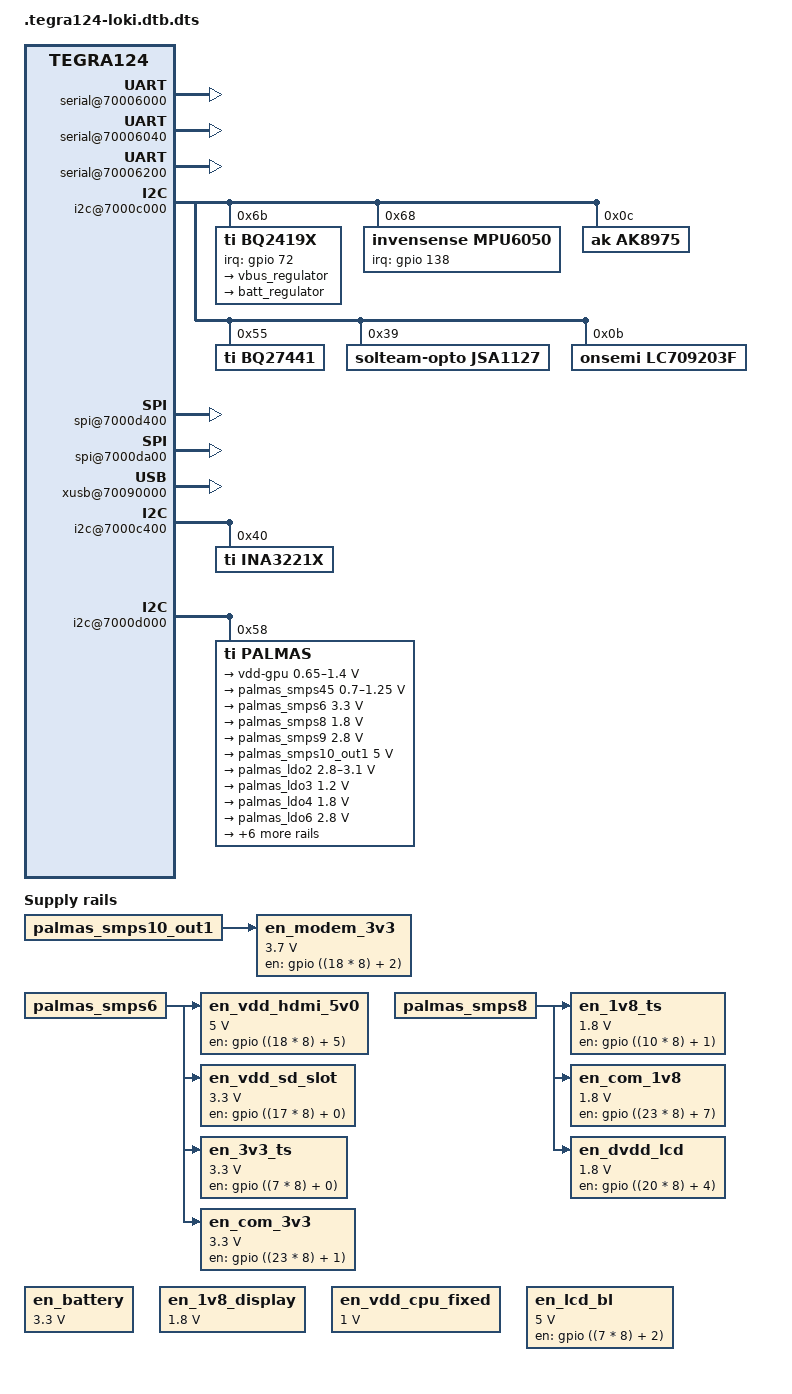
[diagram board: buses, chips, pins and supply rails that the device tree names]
# 1 "arch/arm/boot/dts/tegra124-loki.dts"
# 1 "<built-in>"
# 1 "<command-line>"
# 1 "arch/arm/boot/dts/tegra124-loki.dts"
# 1 "arch/arm/boot/dts/tegra124-loki-e2530-a01.dts" 1
# 1 "arch/arm/boot/dts/tegra124-loki-common.dtsi" 1
/dts-v1/;

# 1 "arch/arm/boot/dts/tegra124.dtsi" 1
# 1 "/media/madman/Extended_Linux/21.8_l4t_build/kernel/arch/arm/boot/dts/include/dt-bindings/gpio/tegra-gpio.h" 1
# 13 "/media/madman/Extended_Linux/21.8_l4t_build/kernel/arch/arm/boot/dts/include/dt-bindings/gpio/tegra-gpio.h"
# 1 "/media/madman/Extended_Linux/21.8_l4t_build/kernel/arch/arm/boot/dts/include/dt-bindings/gpio/gpio.h" 1
# 14 "/media/madman/Extended_Linux/21.8_l4t_build/kernel/arch/arm/boot/dts/include/dt-bindings/gpio/tegra-gpio.h" 2
# 2 "arch/arm/boot/dts/tegra124.dtsi" 2
# 1 "/media/madman/Extended_Linux/21.8_l4t_build/kernel/arch/arm/boot/dts/include/dt-bindings/input/input.h" 1
# 3 "arch/arm/boot/dts/tegra124.dtsi" 2
# 1 "/media/madman/Extended_Linux/21.8_l4t_build/kernel/arch/arm/boot/dts/include/dt-bindings/interrupt-controller/arm-gic.h" 1







# 1 "/media/madman/Extended_Linux/21.8_l4t_build/kernel/arch/arm/boot/dts/include/dt-bindings/interrupt-controller/irq.h" 1
# 9 "/media/madman/Extended_Linux/21.8_l4t_build/kernel/arch/arm/boot/dts/include/dt-bindings/interrupt-controller/arm-gic.h" 2
# 4 "arch/arm/boot/dts/tegra124.dtsi" 2
# 1 "/media/madman/Extended_Linux/21.8_l4t_build/kernel/arch/arm/boot/dts/include/dt-bindings/ata/ahci-tegra.h" 1
# 5 "arch/arm/boot/dts/tegra124.dtsi" 2

/include/ "tegra124-soc.dtsi"

/ {
 compatible = "nvidia,tegra124";
 interrupt-parent = <&intc>;
 #address-cells = <2>;
 #size-cells = <2>;

 mc {
  compatible = "nvidia,tegra-mc";

  reg-ranges = <9>;
  reg = <0x0 0x70019000 0x0 0x00c>,
        <0x0 0x70019050 0x0 0x19c>,
        <0x0 0x70019200 0x0 0x024>,
        <0x0 0x7001929c 0x0 0x1b8>,
        <0x0 0x70019464 0x0 0x198>,
        <0x0 0x70019604 0x0 0x3b0>,
        <0x0 0x700199bc 0x0 0x020>,
        <0x0 0x700199f8 0x0 0x08c>,
        <0x0 0x70019ab4 0x0 0x54c>;

  interrupts = <0 77 0x4>;
  int_count = <8>;
  int_mask = <0x13D40>;

  channels = <1>;
 };

 intc: interrupt-controller@50041000 {
  compatible = "arm,cortex-a15-gic";
  interrupt-controller;
  #interrupt-cells = <3>;
  reg = <0x0 0x50041000 0x0 0x1000>,
        <0x0 0x50042000 0x0 0x0100>;
 };

 lic: interrupt-controller@60004000 {
  compatible = "nvidia,tegra-gic";
  interrupt-controller;
  reg = <0x0 0x60004000 0x0 0x40>,
        <0x0 0x60004100 0x0 0x40>,
        <0x0 0x60004200 0x0 0x40>,
        <0x0 0x60004300 0x0 0x40>,
        <0x0 0x60004400 0x0 0x40>;
        };

 cpus {
  #address-cells = <1>;
  #size-cells = <0>;

  cpu@0 {
   device_type = "cpu";
   compatible = "arm,cortex-a15";
   reg = <0>;
  };

  cpu@1 {
   device_type = "cpu";
   compatible = "arm,cortex-a15";
   reg = <1>;
  };

  cpu@2 {
   device_type = "cpu";
   compatible = "arm,cortex-a15";
   reg = <2>;
  };

  cpu@3 {
   device_type = "cpu";
   compatible = "arm,cortex-a15";
   reg = <3>;
  };
 };

 timer {
  compatible = "arm,armv7-timer";
  interrupts = <1 13 0xf04
         1 14 0xf04>;
 };

 dfll@70110000 {
   compatible = "nvidia,tegra124-dfll";
   reg = <0x0 0x70110000 0x0 0x400>;
   out-clock-name="dfll_cpu";
   status = "disabled";
 };
};
# 4 "arch/arm/boot/dts/tegra124-loki-common.dtsi" 2

# 1 "/media/madman/Extended_Linux/21.8_l4t_build/kernel/arch/arm/boot/dts/tegra124-platforms/tegra124-loki-gpio-default.dtsi" 1


/ {
 gpio: gpio@6000d000 {
  gpio-init-names = "default";
  gpio-init-0 = <&gpio_default>;

  gpio_default: default {
   gpio-input = < ((23 * 8) + 3)
     ((22 * 8) + 3)
     ((6 * 8) + 0)
     ((6 * 8) + 1)
     ((7 * 8) + 4)
     ((6 * 8) + 2)
     ((6 * 8) + 3)
     ((9 * 8) + 0)
     ((9 * 8) + 2)
     ((10 * 8) + 3)
     ((10 * 8) + 2)
     ((8 * 8) + 6)
     ((8 * 8) + 5)
     ((8 * 8) + 1)
     ((2 * 8) + 7)
     ((8 * 8) + 0)
     ((16 * 8) + 0)
     ((16 * 8) + 5)
     ((18 * 8) + 4)
     ((18 * 8) + 6)
     ((18 * 8) + 7)
     ((17 * 8) + 2)
     ((17 * 8) + 4)
     ((17 * 8) + 6)
     ((17 * 8) + 7)
     ((20 * 8) + 0)
     ((20 * 8) + 2)
     ((20 * 8) + 5)
     ((13 * 8) + 7)
     ((10 * 8) + 6)>;
   gpio-output-low = <((23 * 8) + 7)
     ((23 * 8) + 1)
     ((27 * 8) + 3)
     ((27 * 8) + 6)
     ((7 * 8) + 2)
     ((7 * 8) + 3)
     ((7 * 8) + 5)
     ((7 * 8) + 6)
     ((7 * 8) + 7)
     ((7 * 8) + 0)
     ((10 * 8) + 1)
     ((10 * 8) + 4)
     ((8 * 8) + 3)
     ((8 * 8) + 4)
     ((8 * 8) + 7)
     ((28 * 8) + 5)
     ((16 * 8) + 6)
     ((17 * 8) + 0)
     ((17 * 8) + 1)
     ((18 * 8) + 5)
     ((17 * 8) + 3)
     ((30 * 8) + 1)
     ((20 * 8) + 1)
     ((20 * 8) + 4)
     ((10 * 8) + 5)>;
   gpio-output-high = <((10 * 8) + 0)
     ((16 * 8) + 7)
     ((21 * 8) + 3)
     ((17 * 8) + 5)
     ((20 * 8) + 6)>;
  };
 };
};
# 6 "arch/arm/boot/dts/tegra124-loki-common.dtsi" 2
# 1 "/media/madman/Extended_Linux/21.8_l4t_build/kernel/arch/arm/boot/dts/tegra124-platforms/tegra124-loki-pinmux.dtsi" 1
# 1 "/media/madman/Extended_Linux/21.8_l4t_build/kernel/arch/arm/boot/dts/include/dt-bindings/pinctrl/pinctrl-tegra.h" 1
# 2 "/media/madman/Extended_Linux/21.8_l4t_build/kernel/arch/arm/boot/dts/tegra124-platforms/tegra124-loki-pinmux.dtsi" 2

/ {
 pinmux: pinmux {
  pinctrl-names = "default", "drive", "unused";
  pinctrl-0 = <&pinmux_default>;
  pinctrl-1 = <&drive_default>;
  pinctrl-2 = <&pinmux_unused_lowpower>;

  pinmux_default: common {
   dap_mclk1_pw4 {
    nvidia,pins = "dap_mclk1_pw4";
    nvidia,function = "extperiph1";
    nvidia,enable-input = <0>;
    nvidia,pull = <0>;
    nvidia,tristate = <0>;
   };

   dap2_din_pa4 {
    nvidia,pins = "dap2_din_pa4";
    nvidia,function = "i2s1";
    nvidia,enable-input = <1>;
    nvidia,pull = <0>;
    nvidia,tristate = <1>;
   };

   dap2_dout_pa5 {
    nvidia,pins = "dap2_dout_pa5";
    nvidia,function = "i2s1";
    nvidia,enable-input = <1>;
    nvidia,pull = <0>;
    nvidia,tristate = <0>;
   };

   dap2_fs_pa2 {
    nvidia,pins = "dap2_fs_pa2";
    nvidia,function = "i2s1";
    nvidia,enable-input = <1>;
    nvidia,pull = <0>;
    nvidia,tristate = <0>;
   };

   dap2_sclk_pa3 {
    nvidia,pins = "dap2_sclk_pa3";
    nvidia,function = "i2s1";
    nvidia,enable-input = <1>;
    nvidia,pull = <0>;
    nvidia,tristate = <0>;
   };

   dvfs_pwm_px0 {
    nvidia,pins = "dvfs_pwm_px0";
    nvidia,function = "cldvfs";
    nvidia,enable-input = <0>;
    nvidia,pull = <0>;
    nvidia,tristate = <0>;
   };

   dvfs_clk_px2 {
    nvidia,pins = "dvfs_clk_px2";
    nvidia,function = "cldvfs";
    nvidia,enable-input = <0>;
    nvidia,pull = <0>;
    nvidia,tristate = <0>;
   };

   ulpi_clk_py0 {
    nvidia,pins = "ulpi_clk_py0";
    nvidia,function = "spi1";
    nvidia,enable-input = <0>;
    nvidia,pull = <0>;
    nvidia,tristate = <0>;
   };

   ulpi_dir_py1 {
    nvidia,pins = "ulpi_dir_py1";
    nvidia,function = "spi1";
    nvidia,enable-input = <1>;
    nvidia,pull = <0>;
    nvidia,tristate = <0>;
   };

   ulpi_nxt_py2 {
    nvidia,pins = "ulpi_nxt_py2";
    nvidia,function = "spi1";
    nvidia,enable-input = <0>;
    nvidia,pull = <0>;
    nvidia,tristate = <0>;
   };

   ulpi_stp_py3 {
    nvidia,pins = "ulpi_stp_py3";
    nvidia,function = "spi1";
    nvidia,enable-input = <0>;
    nvidia,pull = <0>;
    nvidia,tristate = <0>;
   };

   gen2_i2c_scl_pt5 {
    nvidia,pins = "gen2_i2c_scl_pt5";
    nvidia,function = "i2c2";
    nvidia,enable-input = <1>;
    nvidia,pull = <0>;
    nvidia,tristate = <0>;
    nvidia,lock = <0>;
    nvidia,open-drain = <1>;
   };

   gen2_i2c_sda_pt6 {
    nvidia,pins = "gen2_i2c_sda_pt6";
    nvidia,function = "i2c2";
    nvidia,enable-input = <1>;
    nvidia,pull = <0>;
    nvidia,tristate = <0>;
    nvidia,lock = <0>;
    nvidia,open-drain = <1>;
   };

   cam_i2c_scl_pbb1 {
    nvidia,pins = "cam_i2c_scl_pbb1";
    nvidia,function = "i2c3";
    nvidia,enable-input = <1>;
    nvidia,pull = <0>;
    nvidia,tristate = <0>;
    nvidia,lock = <0>;
    nvidia,open-drain = <1>;
   };

   cam_i2c_sda_pbb2 {
    nvidia,pins = "cam_i2c_sda_pbb2";
    nvidia,function = "i2c3";
    nvidia,enable-input = <1>;
    nvidia,pull = <0>;
    nvidia,tristate = <0>;
    nvidia,lock = <0>;
    nvidia,open-drain = <1>;
   };

   pj7 {
    nvidia,pins = "pj7";
    nvidia,function = "uartd";
    nvidia,enable-input = <0>;
    nvidia,pull = <0>;
    nvidia,tristate = <0>;
   };

   pb0 {
    nvidia,pins = "pb0";
    nvidia,function = "uartd";
    nvidia,enable-input = <1>;
    nvidia,pull = <0>;
    nvidia,tristate = <0>;
   };

   pb1 {
    nvidia,pins = "pb1";
    nvidia,function = "uartd";
    nvidia,enable-input = <1>;
    nvidia,pull = <0>;
    nvidia,tristate = <0>;
   };

   pk7 {
    nvidia,pins = "pk7";
    nvidia,function = "uartd";
    nvidia,enable-input = <0>;
    nvidia,pull = <0>;
    nvidia,tristate = <0>;
   };

   pg4 {
    nvidia,pins = "pg4";
    nvidia,function = "spi4";
    nvidia,enable-input = <0>;
    nvidia,pull = <0>;
    nvidia,tristate = <0>;
   };

   pg5 {
    nvidia,pins = "pg5";
    nvidia,function = "spi4";
    nvidia,enable-input = <0>;
    nvidia,pull = <0>;
    nvidia,tristate = <0>;
   };

   pg6 {
    nvidia,pins = "pg6";
    nvidia,function = "spi4";
    nvidia,enable-input = <0>;
    nvidia,pull = <0>;
    nvidia,tristate = <0>;
   };

   pg7 {
    nvidia,pins = "pg7";
    nvidia,function = "spi4";
    nvidia,enable-input = <1>;
    nvidia,pull = <0>;
    nvidia,tristate = <0>;
   };

   ph1 {
    nvidia,pins = "ph1";
    nvidia,function = "pwm1";
    nvidia,enable-input = <0>;
    nvidia,pull = <0>;
    nvidia,tristate = <0>;
   };

   clk2_out_pw5 {
    nvidia,pins = "clk2_out_pw5";
    nvidia,function = "extperiph2";
    nvidia,enable-input = <0>;
    nvidia,pull = <0>;
    nvidia,tristate = <0>;
   };

   sdmmc1_clk_pz0 {
    nvidia,pins = "sdmmc1_clk_pz0";
    nvidia,function = "sdmmc1";
    nvidia,enable-input = <1>;
    nvidia,pull = <0>;
    nvidia,tristate = <0>;
   };

   sdmmc1_cmd_pz1 {
    nvidia,pins = "sdmmc1_cmd_pz1";
    nvidia,function = "sdmmc1";
    nvidia,enable-input = <1>;
    nvidia,pull = <2>;
    nvidia,tristate = <0>;
   };

   sdmmc1_dat0_py7 {
    nvidia,pins = "sdmmc1_dat0_py7";
    nvidia,function = "sdmmc1";
    nvidia,enable-input = <1>;
    nvidia,pull = <2>;
    nvidia,tristate = <0>;
   };

   sdmmc1_dat1_py6 {
    nvidia,pins = "sdmmc1_dat1_py6";
    nvidia,function = "sdmmc1";
    nvidia,enable-input = <1>;
    nvidia,pull = <2>;
    nvidia,tristate = <0>;
   };

   sdmmc1_dat2_py5 {
    nvidia,pins = "sdmmc1_dat2_py5";
    nvidia,function = "sdmmc1";
    nvidia,enable-input = <1>;
    nvidia,pull = <2>;
    nvidia,tristate = <0>;
   };

   sdmmc1_dat3_py4 {
    nvidia,pins = "sdmmc1_dat3_py4";
    nvidia,function = "sdmmc1";
    nvidia,enable-input = <1>;
    nvidia,pull = <2>;
    nvidia,tristate = <0>;
   };

   sdmmc3_clk_pa6 {
    nvidia,pins = "sdmmc3_clk_pa6";
    nvidia,function = "sdmmc3";
    nvidia,enable-input = <0>;
    nvidia,pull = <0>;
    nvidia,tristate = <0>;
   };

   sdmmc3_cmd_pa7 {
    nvidia,pins = "sdmmc3_cmd_pa7";
    nvidia,function = "sdmmc3";
    nvidia,enable-input = <1>;
    nvidia,pull = <2>;
    nvidia,tristate = <0>;
   };

   sdmmc3_dat0_pb7 {
    nvidia,pins = "sdmmc3_dat0_pb7";
    nvidia,function = "sdmmc3";
    nvidia,enable-input = <1>;
    nvidia,pull = <2>;
    nvidia,tristate = <0>;
   };

   sdmmc3_dat1_pb6 {
    nvidia,pins = "sdmmc3_dat1_pb6";
    nvidia,function = "sdmmc3";
    nvidia,enable-input = <1>;
    nvidia,pull = <2>;
    nvidia,tristate = <0>;
   };

   sdmmc3_dat2_pb5 {
    nvidia,pins = "sdmmc3_dat2_pb5";
    nvidia,function = "sdmmc3";
    nvidia,enable-input = <1>;
    nvidia,pull = <2>;
    nvidia,tristate = <0>;
   };

   sdmmc3_dat3_pb4 {
    nvidia,pins = "sdmmc3_dat3_pb4";
    nvidia,function = "sdmmc3";
    nvidia,enable-input = <1>;
    nvidia,pull = <2>;
    nvidia,tristate = <0>;
   };

   sdmmc3_clk_lb_out_pee4 {
    nvidia,pins = "sdmmc3_clk_lb_out_pee4";
    nvidia,function = "sdmmc3";
    nvidia,enable-input = <1>;
    nvidia,pull = <2>;
    nvidia,tristate = <0>;
   };

   sdmmc3_clk_lb_in_pee5 {
    nvidia,pins = "sdmmc3_clk_lb_in_pee5";
    nvidia,function = "sdmmc3";
    nvidia,enable-input = <1>;
    nvidia,pull = <2>;
    nvidia,tristate = <0>;
   };

   sdmmc3_cd_n_pv2 {
    nvidia,pins = "sdmmc3_cd_n_pv2";
    nvidia,function = "sdmmc3";
    nvidia,enable-input = <1>;
    nvidia,pull = <2>;
    nvidia,tristate = <0>;
   };

   sdmmc4_clk_pcc4 {
    nvidia,pins = "sdmmc4_clk_pcc4";
    nvidia,function = "sdmmc4";
    nvidia,enable-input = <1>;
    nvidia,pull = <0>;
    nvidia,tristate = <0>;
   };

   sdmmc4_cmd_pt7 {
    nvidia,pins = "sdmmc4_cmd_pt7";
    nvidia,function = "sdmmc4";
    nvidia,enable-input = <1>;
    nvidia,pull = <2>;
    nvidia,tristate = <0>;
   };

   sdmmc4_dat0_paa0 {
    nvidia,pins = "sdmmc4_dat0_paa0";
    nvidia,function = "sdmmc4";
    nvidia,enable-input = <1>;
    nvidia,pull = <2>;
    nvidia,tristate = <0>;
   };

   sdmmc4_dat1_paa1 {
    nvidia,pins = "sdmmc4_dat1_paa1";
    nvidia,function = "sdmmc4";
    nvidia,enable-input = <1>;
    nvidia,pull = <2>;
    nvidia,tristate = <0>;
   };

   sdmmc4_dat2_paa2 {
    nvidia,pins = "sdmmc4_dat2_paa2";
    nvidia,function = "sdmmc4";
    nvidia,enable-input = <1>;
    nvidia,pull = <2>;
    nvidia,tristate = <0>;
   };

   sdmmc4_dat3_paa3 {
    nvidia,pins = "sdmmc4_dat3_paa3";
    nvidia,function = "sdmmc4";
    nvidia,enable-input = <1>;
    nvidia,pull = <2>;
    nvidia,tristate = <0>;
   };

   sdmmc4_dat4_paa4 {
    nvidia,pins = "sdmmc4_dat4_paa4";
    nvidia,function = "sdmmc4";
    nvidia,enable-input = <1>;
    nvidia,pull = <2>;
    nvidia,tristate = <0>;
   };

   sdmmc4_dat5_paa5 {
    nvidia,pins = "sdmmc4_dat5_paa5";
    nvidia,function = "sdmmc4";
    nvidia,enable-input = <1>;
    nvidia,pull = <2>;
    nvidia,tristate = <0>;
   };

   sdmmc4_dat6_paa6 {
    nvidia,pins = "sdmmc4_dat6_paa6";
    nvidia,function = "sdmmc4";
    nvidia,enable-input = <1>;
    nvidia,pull = <2>;
    nvidia,tristate = <0>;
   };

   sdmmc4_dat7_paa7 {
    nvidia,pins = "sdmmc4_dat7_paa7";
    nvidia,function = "sdmmc4";
    nvidia,enable-input = <1>;
    nvidia,pull = <2>;
    nvidia,tristate = <0>;
   };

   kb_col3_pq3 {
    nvidia,pins = "kb_col3_pq3";
    nvidia,function = "pwm2";
    nvidia,enable-input = <0>;
    nvidia,pull = <0>;
    nvidia,tristate = <0>;
   };

   clk_32k_out_pa0 {
    nvidia,pins = "clk_32k_out_pa0";
    nvidia,function = "soc";
    nvidia,enable-input = <1>;
    nvidia,pull = <2>;
    nvidia,tristate = <0>;
   };

   pwr_i2c_scl_pz6 {
    nvidia,pins = "pwr_i2c_scl_pz6";
    nvidia,function = "i2cpwr";
    nvidia,enable-input = <1>;
    nvidia,pull = <0>;
    nvidia,tristate = <0>;
    nvidia,open-drain = <1>;
   };

   pwr_i2c_sda_pz7 {
    nvidia,pins = "pwr_i2c_sda_pz7";
    nvidia,function = "i2cpwr";
    nvidia,enable-input = <1>;
    nvidia,pull = <0>;
    nvidia,tristate = <0>;
    nvidia,open-drain = <1>;
   };

   jtag_rtck {
    nvidia,pins = "jtag_rtck";
    nvidia,function = "rtck";
    nvidia,enable-input = <0>;
    nvidia,pull = <0>;
    nvidia,tristate = <0>;
   };

   clk_32k_in {
    nvidia,pins = "clk_32k_in";
    nvidia,function = "clk";
    nvidia,enable-input = <1>;
    nvidia,pull = <0>;
    nvidia,tristate = <0>;
   };

   core_pwr_req {
    nvidia,pins = "core_pwr_req";
    nvidia,function = "pwron";
    nvidia,enable-input = <0>;
    nvidia,pull = <0>;
    nvidia,tristate = <0>;
   };

   cpu_pwr_req {
    nvidia,pins = "cpu_pwr_req";
    nvidia,function = "cpu";
    nvidia,enable-input = <0>;
    nvidia,pull = <0>;
    nvidia,tristate = <0>;
   };

   pwr_int_n {
    nvidia,pins = "pwr_int_n";
    nvidia,function = "pmi";
    nvidia,enable-input = <1>;
    nvidia,pull = <0>;
    nvidia,tristate = <0>;
   };

   reset_out_n {
    nvidia,pins = "reset_out_n";
    nvidia,function = "reset_out_n";
    nvidia,enable-input = <0>;
    nvidia,pull = <0>;
    nvidia,tristate = <0>;
   };

   dap4_din_pp5 {
    nvidia,pins = "dap4_din_pp5";
    nvidia,function = "i2s3";
    nvidia,enable-input = <1>;
    nvidia,pull = <0>;
    nvidia,tristate = <0>;
   };

   dap4_dout_pp6 {
    nvidia,pins = "dap4_dout_pp6";
    nvidia,function = "i2s3";
    nvidia,enable-input = <0>;
    nvidia,pull = <0>;
    nvidia,tristate = <0>;
   };

   dap4_fs_pp4 {
    nvidia,pins = "dap4_fs_pp4";
    nvidia,function = "i2s3";
    nvidia,enable-input = <0>;
    nvidia,pull = <0>;
    nvidia,tristate = <0>;
   };

   dap4_sclk_pp7 {
    nvidia,pins = "dap4_sclk_pp7";
    nvidia,function = "i2s3";
    nvidia,enable-input = <0>;
    nvidia,pull = <0>;
    nvidia,tristate = <0>;
   };

   gen1_i2c_sda_pc5 {
    nvidia,pins = "gen1_i2c_sda_pc5";
    nvidia,function = "i2c1";
    nvidia,enable-input = <1>;
    nvidia,pull = <0>;
    nvidia,tristate = <0>;
    nvidia,lock = <0>;
    nvidia,open-drain = <1>;
   };

   gen1_i2c_scl_pc4 {
    nvidia,pins = "gen1_i2c_scl_pc4";
    nvidia,function = "i2c1";
    nvidia,enable-input = <1>;
    nvidia,pull = <0>;
    nvidia,tristate = <0>;
    nvidia,lock = <0>;
    nvidia,open-drain = <1>;
   };

   pu3 {
    nvidia,pins = "pu3";
    nvidia,function = "pwm0";
    nvidia,enable-input = <0>;
    nvidia,pull = <0>;
    nvidia,tristate = <0>;
   };

   uart2_cts_n_pj5 {
    nvidia,pins = "uart2_cts_n_pj5";
    nvidia,function = "uartb";
    nvidia,enable-input = <1>;
    nvidia,pull = <2>;
    nvidia,tristate = <0>;
   };

   uart2_rts_n_pj6 {
    nvidia,pins = "uart2_rts_n_pj6";
    nvidia,function = "uartb";
    nvidia,enable-input = <0>;
    nvidia,pull = <2>;
    nvidia,tristate = <0>;
   };

   uart2_rxd_pc3 {
    nvidia,pins = "uart2_rxd_pc3";
    nvidia,function = "irda";
    nvidia,enable-input = <1>;
    nvidia,pull = <2>;
    nvidia,tristate = <0>;
   };

   uart2_txd_pc2 {
    nvidia,pins = "uart2_txd_pc2";
    nvidia,function = "irda";
    nvidia,enable-input = <0>;
    nvidia,pull = <2>;
    nvidia,tristate = <0>;
   };

   uart3_cts_n_pa1 {
    nvidia,pins = "uart3_cts_n_pa1";
    nvidia,function = "uartc";
    nvidia,enable-input = <1>;
    nvidia,pull = <2>;
    nvidia,tristate = <0>;
   };

   uart3_rts_n_pc0 {
    nvidia,pins = "uart3_rts_n_pc0";
    nvidia,function = "uartc";
    nvidia,enable-input = <0>;
    nvidia,pull = <2>;
    nvidia,tristate = <0>;
   };

   uart3_rxd_pw7 {
    nvidia,pins = "uart3_rxd_pw7";
    nvidia,function = "uartc";
    nvidia,enable-input = <1>;
    nvidia,pull = <2>;
    nvidia,tristate = <0>;
   };

   uart3_txd_pw6 {
    nvidia,pins = "uart3_txd_pw6";
    nvidia,function = "uartc";
    nvidia,enable-input = <0>;
    nvidia,pull = <2>;
    nvidia,tristate = <0>;
   };

   sdmmc1_wp_n_pv3 {
    nvidia,pins = "sdmmc1_wp_n_pv3";
    nvidia,function = "spi4";
    nvidia,enable-input = <0>;
    nvidia,pull = <2>;
    nvidia,tristate = <0>;
   };

   hdmi_cec_pee3 {
    nvidia,pins = "hdmi_cec_pee3";
    nvidia,function = "cec";
    nvidia,enable-input = <1>;
    nvidia,pull = <0>;
    nvidia,tristate = <0>;
    nvidia,open-drain = <1>;
   };

   ddc_scl_pv4 {
    nvidia,pins = "ddc_scl_pv4";
    nvidia,function = "i2c4";
    nvidia,enable-input = <1>;
    nvidia,pull = <0>;
    nvidia,tristate = <0>;
    nvidia,rcv-sel = <0>;
   };

   ddc_sda_pv5 {
    nvidia,pins = "ddc_sda_pv5";
    nvidia,function = "i2c4";
    nvidia,enable-input = <1>;
    nvidia,pull = <0>;
    nvidia,tristate = <0>;
    nvidia,rcv-sel = <0>;
   };

   gpio_x3_aud_px3 {
    nvidia,pins = "gpio_x3_aud_px3";
    nvidia,function = "safe";
    nvidia,enable-input = <1>;
    nvidia,pull = <2>;
    nvidia,tristate = <0>;
   };

   gpio_x7_aud_px7 {
    nvidia,pins = "gpio_x7_aud_px7";
    nvidia,function = "safe";
    nvidia,enable-input = <0>;
    nvidia,pull = <1>;
    nvidia,tristate = <0>;
   };

   gpio_w3_aud_pw3 {
    nvidia,pins = "gpio_w3_aud_pw3";
    nvidia,function = "safe";
    nvidia,enable-input = <1>;
    nvidia,pull = <0>;
    nvidia,tristate = <0>;
   };

   gpio_x1_aud_px1 {
    nvidia,pins = "gpio_x1_aud_px1";
    nvidia,function = "safe";
    nvidia,enable-input = <0>;
    nvidia,pull = <1>;
    nvidia,tristate = <0>;
   };

   pbb3 {
    nvidia,pins = "pbb3";
    nvidia,function = "safe";
    nvidia,enable-input = <0>;
    nvidia,pull = <0>;
    nvidia,tristate = <0>;
   };

   pbb6 {
    nvidia,pins = "pbb6";
    nvidia,function = "safe";
    nvidia,enable-input = <0>;
    nvidia,pull = <0>;
    nvidia,tristate = <0>;
   };

   pg0 {
    nvidia,pins = "pg0";
    nvidia,function = "safe";
    nvidia,enable-input = <1>;
    nvidia,pull = <0>;
    nvidia,tristate = <0>;
   };

   pg1 {
    nvidia,pins = "pg1";
    nvidia,function = "safe";
    nvidia,enable-input = <1>;
    nvidia,pull = <0>;
    nvidia,tristate = <0>;
   };

   ph4 {
    nvidia,pins = "ph4";
    nvidia,function = "safe";
    nvidia,enable-input = <1>;
    nvidia,pull = <0>;
    nvidia,tristate = <0>;
   };

   ph5 {
    nvidia,pins = "ph5";
    nvidia,function = "safe";
    nvidia,enable-input = <0>;
    nvidia,pull = <1>;
    nvidia,tristate = <0>;
   };

   ph6 {
    nvidia,pins = "ph6";
    nvidia,function = "safe";
    nvidia,enable-input = <0>;
    nvidia,pull = <0>;
    nvidia,tristate = <0>;
   };

   ph7 {
    nvidia,pins = "ph7";
    nvidia,function = "safe";
    nvidia,enable-input = <0>;
    nvidia,pull = <0>;
    nvidia,tristate = <0>;
   };

   pg2 {
    nvidia,pins = "pg2";
    nvidia,function = "safe";
    nvidia,enable-input = <1>;
    nvidia,pull = <0>;
    nvidia,tristate = <0>;
   };

   pg3 {
    nvidia,pins = "pg3";
    nvidia,function = "safe";
    nvidia,enable-input = <1>;
    nvidia,pull = <0>;
    nvidia,tristate = <0>;
   };

   ph0 {
    nvidia,pins = "ph0";
    nvidia,function = "safe";
    nvidia,enable-input = <0>;
    nvidia,pull = <1>;
    nvidia,tristate = <0>;
   };

   pk0 {
    nvidia,pins = "pk0";
    nvidia,function = "safe";
    nvidia,enable-input = <0>;
    nvidia,pull = <2>;
    nvidia,tristate = <0>;
   };

   kb_col7_pq7 {
    nvidia,pins = "kb_col7_pq7";
    nvidia,function = "safe";
    nvidia,enable-input = <0>;
    nvidia,pull = <2>;
    nvidia,tristate = <0>;
   };

   pk1 {
    nvidia,pins = "pk1";
    nvidia,function = "safe";
    nvidia,enable-input = <0>;
    nvidia,pull = <1>;
    nvidia,tristate = <0>;
   };

   pj0 {
    nvidia,pins = "pj0";
    nvidia,function = "safe";
    nvidia,enable-input = <1>;
    nvidia,pull = <2>;
    nvidia,tristate = <0>;
   };

   pj2 {
    nvidia,pins = "pj2";
    nvidia,function = "safe";
    nvidia,enable-input = <1>;
    nvidia,pull = <2>;
    nvidia,tristate = <0>;
   };

   pk3 {
    nvidia,pins = "pk3";
    nvidia,function = "safe";
    nvidia,enable-input = <1>;
    nvidia,pull = <2>;
    nvidia,tristate = <0>;
   };

   pk4 {
    nvidia,pins = "pk4";
    nvidia,function = "safe";
    nvidia,enable-input = <0>;
    nvidia,pull = <2>;
    nvidia,tristate = <0>;
   };

   pk2 {
    nvidia,pins = "pk2";
    nvidia,function = "safe";
    nvidia,enable-input = <1>;
    nvidia,pull = <2>;
    nvidia,tristate = <0>;
   };

   pi3 {
    nvidia,pins = "pi3";
    nvidia,function = "safe";
    nvidia,enable-input = <0>;
    nvidia,pull = <0>;
    nvidia,tristate = <0>;
   };

   pi6 {
    nvidia,pins = "pi6";
    nvidia,function = "safe";
    nvidia,enable-input = <1>;
    nvidia,pull = <2>;
    nvidia,tristate = <0>;
   };

   pi5 {
    nvidia,pins = "pi5";
    nvidia,function = "safe";
    nvidia,enable-input = <1>;
    nvidia,pull = <2>;
    nvidia,tristate = <0>;
   };

   pi1 {
    nvidia,pins = "pi1";
    nvidia,function = "safe";
    nvidia,enable-input = <1>;
    nvidia,pull = <0>;
    nvidia,tristate = <0>;
   };

   pi4 {
    nvidia,pins = "pi4";
    nvidia,function = "safe";
    nvidia,enable-input = <0>;
    nvidia,pull = <1>;
    nvidia,tristate = <0>;
   };

   pi7 {
    nvidia,pins = "pi7";
    nvidia,function = "safe";
    nvidia,enable-input = <0>;
    nvidia,pull = <1>;
    nvidia,tristate = <0>;
   };

   pc7 {
    nvidia,pins = "pc7";
    nvidia,function = "safe";
    nvidia,enable-input = <1>;
    nvidia,pull = <0>;
    nvidia,tristate = <0>;
   };

   pi0 {
    nvidia,pins = "pi0";
    nvidia,function = "safe";
    nvidia,enable-input = <1>;
    nvidia,pull = <0>;
    nvidia,tristate = <0>;
   };

   clk2_req_pcc5 {
    nvidia,pins = "clk2_req_pcc5";
    nvidia,function = "safe";
    nvidia,enable-input = <0>;
    nvidia,pull = <1>;
    nvidia,tristate = <0>;
   };

   kb_col0_pq0 {
    nvidia,pins = "kb_col0_pq0";
    nvidia,function = "safe";
    nvidia,enable-input = <1>;
    nvidia,pull = <2>;
    nvidia,tristate = <0>;
   };

   kb_col2_pq2 {
    nvidia,pins = "kb_col2_pq2";
    nvidia,function = "safe";
    nvidia,enable-input = <0>;
    nvidia,pull = <0>;
    nvidia,tristate = <0>;
   };

   kb_col5_pq5 {
    nvidia,pins = "kb_col5_pq5";
    nvidia,function = "safe";
    nvidia,enable-input = <1>;
    nvidia,pull = <2>;
    nvidia,tristate = <0>;
   };

   kb_col6_pq6 {
    nvidia,pins = "kb_col6_pq6";
    nvidia,function = "safe";
    nvidia,enable-input = <0>;
    nvidia,pull = <1>;
    nvidia,tristate = <0>;
   };

   kb_row0_pr0 {
    nvidia,pins = "kb_row0_pr0";
    nvidia,function = "safe";
    nvidia,enable-input = <0>;
    nvidia,pull = <1>;
    nvidia,tristate = <0>;
   };

   kb_row1_pr1 {
    nvidia,pins = "kb_row1_pr1";
    nvidia,function = "safe";
    nvidia,enable-input = <0>;
    nvidia,pull = <1>;
    nvidia,tristate = <0>;
   };

   kb_row10_ps2 {
    nvidia,pins = "kb_row10_ps2";
    nvidia,function = "safe";
    nvidia,enable-input = <0>;
    nvidia,pull = <0>;
    nvidia,tristate = <0>;
   };

   kb_row11_ps3 {
    nvidia,pins = "kb_row11_ps3";
    nvidia,function = "safe";
    nvidia,enable-input = <0>;
    nvidia,pull = <0>;
    nvidia,tristate = <0>;
   };

   kb_row12_ps4 {
    nvidia,pins = "kb_row12_ps4";
    nvidia,function = "safe";
    nvidia,enable-input = <0>;
    nvidia,pull = <2>;
    nvidia,tristate = <0>;
   };

   kb_row13_ps5 {
    nvidia,pins = "kb_row13_ps5";
    nvidia,function = "safe";
    nvidia,enable-input = <0>;
    nvidia,pull = <1>;
    nvidia,tristate = <0>;
   };

   kb_row14_ps6 {
    nvidia,pins = "kb_row14_ps6";
    nvidia,function = "safe";
    nvidia,enable-input = <1>;
    nvidia,pull = <1>;
    nvidia,tristate = <0>;
   };

   kb_row15_ps7 {
    nvidia,pins = "kb_row15_ps7";
    nvidia,function = "safe";
    nvidia,enable-input = <1>;
    nvidia,pull = <1>;
    nvidia,tristate = <0>;
   };

   kb_row2_pr2 {
    nvidia,pins = "kb_row2_pr2";
    nvidia,function = "safe";
    nvidia,enable-input = <1>;
    nvidia,pull = <2>;
    nvidia,tristate = <0>;
   };

   kb_row3_pr3 {
    nvidia,pins = "kb_row3_pr3";
    nvidia,function = "safe";
    nvidia,enable-input = <0>;
    nvidia,pull = <0>;
    nvidia,tristate = <0>;
   };

   kb_row4_pr4 {
    nvidia,pins = "kb_row4_pr4";
    nvidia,function = "safe";
    nvidia,enable-input = <1>;
    nvidia,pull = <2>;
    nvidia,tristate = <0>;
   };

   kb_row5_pr5 {
    nvidia,pins = "kb_row5_pr5";
    nvidia,function = "safe";
    nvidia,enable-input = <0>;
    nvidia,pull = <2>;
    nvidia,tristate = <0>;
   };

   kb_row6_pr6 {
    nvidia,pins = "kb_row6_pr6";
    nvidia,function = "safe";
    nvidia,enable-input = <1>;
    nvidia,pull = <0>;
    nvidia,tristate = <0>;
   };

   kb_row7_pr7 {
    nvidia,pins = "kb_row7_pr7";
    nvidia,function = "safe";
    nvidia,enable-input = <1>;
    nvidia,pull = <2>;
    nvidia,tristate = <0>;
   };

   kb_row8_ps0 {
    nvidia,pins = "kb_row8_ps0";
    nvidia,function = "safe";
    nvidia,enable-input = <1>;
    nvidia,pull = <2>;
    nvidia,tristate = <0>;
   };

   clk3_req_pee1 {
    nvidia,pins = "clk3_req_pee1";
    nvidia,function = "safe";
    nvidia,enable-input = <0>;
    nvidia,pull = <1>;
    nvidia,tristate = <0>;
   };

   pu1 {
    nvidia,pins = "pu1";
    nvidia,function = "safe";
    nvidia,enable-input = <0>;
    nvidia,pull = <1>;
    nvidia,tristate = <0>;
   };

   pu2 {
    nvidia,pins = "pu2";
    nvidia,function = "safe";
    nvidia,enable-input = <1>;
    nvidia,pull = <0>;
    nvidia,tristate = <0>;
   };

   pu4 {
    nvidia,pins = "pu4";
    nvidia,function = "safe";
    nvidia,enable-input = <0>;
    nvidia,pull = <1>;
    nvidia,tristate = <0>;
   };

   pu5 {
    nvidia,pins = "pu5";
    nvidia,function = "safe";
    nvidia,enable-input = <1>;
    nvidia,pull = <2>;
    nvidia,tristate = <0>;
   };

   pu6 {
    nvidia,pins = "pu6";
    nvidia,function = "safe";
    nvidia,enable-input = <0>;
    nvidia,pull = <0>;
    nvidia,tristate = <0>;
   };

   hdmi_int_pn7 {
    nvidia,pins = "hdmi_int_pn7";
    nvidia,function = "safe";
    nvidia,enable-input = <1>;
    nvidia,pull = <1>;
    nvidia,tristate = <0>;
   };

   spdif_out_pk5 {
    nvidia,pins = "spdif_out_pk5";
    nvidia,function = "safe";
    nvidia,enable-input = <0>;
    nvidia,pull = <1>;
    nvidia,tristate = <0>;
   };

   spdif_in_pk6 {
    nvidia,pins = "spdif_in_pk6";
    nvidia,function = "safe";
    nvidia,enable-input = <1>;
    nvidia,pull = <2>;
    nvidia,tristate = <0>;
   };
  };

  drive_default: drive_pins {
   drive_sdio1 {
    nvidia,pins = "drive_sdio1";
    nvidia,high-speed-mode = <1>;
    nvidia,schmitt = <0>;
    nvidia,pull-down-strength = <54>;
    nvidia,pull-up-strength = <70>;
    nvidia,slew-rate-rising = <0>;
    nvidia,slew-rate-falling = <0>;
   };

   drive_sdio3 {
    nvidia,pins = "drive_sdio3";
    nvidia,high-speed-mode = <1>;
    nvidia,schmitt = <0>;
    nvidia,pull-down-strength = <20>;
    nvidia,pull-up-strength = <42>;
    nvidia,slew-rate-rising = <0>;
    nvidia,slew-rate-falling = <0>;
   };

   drive_gma {
    nvidia,pins = "drive_gma";
    nvidia,high-speed-mode = <1>;
    nvidia,schmitt = <0>;
    nvidia,low-power-mode = <3>;
    nvidia,pull-down-strength = <1>;
    nvidia,pull-up-strength = <2>;
    nvidia,slew-rate-rising = <0>;
    nvidia,slew-rate-falling = <0>;
    nvidia,drive-type = <1>;
   };

   drive_uda {
    nvidia,pins = "drive_uda";
    nvidia,high-speed-mode = <0>;
    nvidia,schmitt = <0>;
    nvidia,pull-down-strength = <8>;
    nvidia,pull-up-strength = <8>;
    nvidia,slew-rate-rising = <3>;
    nvidia,slew-rate-falling = <3>;
   };
  };


  pinmux_unused_lowpower: unused_pins {
   dap_mclk1_req_pee2 {
    nvidia,pins = "dap_mclk1_req_pee2";
    nvidia,function = "safe";
    nvidia,enable-input = <0>;
    nvidia,pull = <1>;
    nvidia,tristate = <1>;
   };

   dap1_din_pn1 {
    nvidia,pins = "dap1_din_pn1";
    nvidia,function = "safe";
    nvidia,enable-input = <0>;
    nvidia,pull = <1>;
    nvidia,tristate = <1>;
   };

   dap1_dout_pn2 {
    nvidia,pins = "dap1_dout_pn2";
    nvidia,function = "safe";
    nvidia,enable-input = <0>;
    nvidia,pull = <1>;
    nvidia,tristate = <1>;
   };

   dap1_fs_pn0 {
    nvidia,pins = "dap1_fs_pn0";
    nvidia,function = "safe";
    nvidia,enable-input = <0>;
    nvidia,pull = <1>;
    nvidia,tristate = <1>;
   };

   dap1_sclk_pn3 {
    nvidia,pins = "dap1_sclk_pn3";
    nvidia,function = "safe";
    nvidia,enable-input = <0>;
    nvidia,pull = <1>;
    nvidia,tristate = <1>;
   };

   gpio_x4_aud_px4 {
    nvidia,pins = "gpio_x4_aud_px4";
    nvidia,function = "safe";
    nvidia,enable-input = <0>;
    nvidia,pull = <1>;
    nvidia,tristate = <1>;
   };

   gpio_x5_aud_px5 {
    nvidia,pins = "gpio_x5_aud_px5";
    nvidia,function = "safe";
    nvidia,enable-input = <0>;
    nvidia,pull = <1>;
    nvidia,tristate = <1>;
   };

   gpio_w2_aud_pw2 {
    nvidia,pins = "gpio_w2_aud_pw2";
    nvidia,function = "safe";
    nvidia,enable-input = <0>;
    nvidia,pull = <1>;
    nvidia,tristate = <1>;
   };

   gpio_x6_aud_px6 {
    nvidia,pins = "gpio_x6_aud_px6";
    nvidia,function = "safe";
    nvidia,enable-input = <0>;
    nvidia,pull = <1>;
    nvidia,tristate = <1>;
   };

   dap3_din_pp1 {
    nvidia,pins = "dap3_din_pp1";
    nvidia,function = "safe";
    nvidia,enable-input = <0>;
    nvidia,pull = <1>;
    nvidia,tristate = <1>;
   };

   dap3_dout_pp2 {
    nvidia,pins = "dap3_dout_pp2";
    nvidia,function = "safe";
    nvidia,enable-input = <0>;
    nvidia,pull = <1>;
    nvidia,tristate = <1>;
   };

   dap3_fs_pp0 {
    nvidia,pins = "dap3_fs_pp0";
    nvidia,function = "safe";
    nvidia,enable-input = <0>;
    nvidia,pull = <1>;
    nvidia,tristate = <1>;
   };

   dap3_sclk_pp3 {
    nvidia,pins = "dap3_sclk_pp3";
    nvidia,function = "safe";
    nvidia,enable-input = <0>;
    nvidia,pull = <1>;
    nvidia,tristate = <1>;
   };

   pv0 {
    nvidia,pins = "pv0";
    nvidia,function = "safe";
    nvidia,enable-input = <0>;
    nvidia,pull = <1>;
    nvidia,tristate = <1>;
   };

   pv1 {
    nvidia,pins = "pv1";
    nvidia,function = "safe";
    nvidia,enable-input = <0>;
    nvidia,pull = <1>;
    nvidia,tristate = <1>;
   };

   ulpi_data0_po1 {
    nvidia,pins = "ulpi_data0_po1";
    nvidia,function = "safe";
    nvidia,enable-input = <0>;
    nvidia,pull = <1>;
    nvidia,tristate = <1>;
   };

   ulpi_data1_po2 {
    nvidia,pins = "ulpi_data1_po2";
    nvidia,function = "safe";
    nvidia,enable-input = <0>;
    nvidia,pull = <1>;
    nvidia,tristate = <1>;
   };

   ulpi_data2_po3 {
    nvidia,pins = "ulpi_data2_po3";
    nvidia,function = "safe";
    nvidia,enable-input = <0>;
    nvidia,pull = <1>;
    nvidia,tristate = <1>;
   };

   ulpi_data3_po4 {
    nvidia,pins = "ulpi_data3_po4";
    nvidia,function = "safe";
    nvidia,enable-input = <0>;
    nvidia,pull = <1>;
    nvidia,tristate = <1>;
   };

   ulpi_data5_po6 {
    nvidia,pins = "ulpi_data5_po6";
    nvidia,function = "safe";
    nvidia,enable-input = <0>;
    nvidia,pull = <1>;
    nvidia,tristate = <1>;
   };

   ulpi_data6_po7 {
    nvidia,pins = "ulpi_data6_po7";
    nvidia,function = "safe";
    nvidia,enable-input = <0>;
    nvidia,pull = <1>;
    nvidia,tristate = <1>;
   };

   ulpi_data7_po0 {
    nvidia,pins = "ulpi_data7_po0";
    nvidia,function = "safe";
    nvidia,enable-input = <0>;
    nvidia,pull = <1>;
    nvidia,tristate = <1>;
   };

   cam_mclk_pcc0 {
    nvidia,pins = "cam_mclk_pcc0";
    nvidia,function = "vi_alt3";
    nvidia,enable-input = <0>;
    nvidia,pull = <0>;
    nvidia,tristate = <0>;
   };

   pbb0 {
    nvidia,pins = "pbb0";
    nvidia,function = "safe";
    nvidia,enable-input = <0>;
    nvidia,pull = <1>;
    nvidia,tristate = <1>;
   };

   pbb4 {
    nvidia,pins = "pbb4";
    nvidia,function = "safe";
    nvidia,enable-input = <0>;
    nvidia,pull = <1>;
    nvidia,tristate = <1>;
   };

   pbb5 {
    nvidia,pins = "pbb5";
    nvidia,function = "safe";
    nvidia,enable-input = <0>;
    nvidia,pull = <1>;
    nvidia,tristate = <1>;
   };

   pbb7 {
    nvidia,pins = "pbb7";
    nvidia,function = "safe";
    nvidia,enable-input = <0>;
    nvidia,pull = <1>;
    nvidia,tristate = <1>;
   };

   pcc1 {
    nvidia,pins = "pcc1";
    nvidia,function = "safe";
    nvidia,enable-input = <0>;
    nvidia,pull = <1>;
    nvidia,tristate = <1>;
   };

   pcc2 {
    nvidia,pins = "pcc2";
    nvidia,function = "safe";
    nvidia,enable-input = <0>;
    nvidia,pull = <1>;
    nvidia,tristate = <1>;
   };

   pi2 {
    nvidia,pins = "pi2";
    nvidia,function = "safe";
    nvidia,enable-input = <0>;
    nvidia,pull = <1>;
    nvidia,tristate = <1>;
   };

   pex_l0_clkreq_n_pdd2 {
    nvidia,pins = "pex_l0_clkreq_n_pdd2";
    nvidia,function = "safe";
    nvidia,enable-input = <0>;
    nvidia,pull = <1>;
    nvidia,tristate = <1>;
   };

   pex_l0_rst_n_pdd1 {
    nvidia,pins = "pex_l0_rst_n_pdd1";
    nvidia,function = "safe";
    nvidia,enable-input = <0>;
    nvidia,pull = <1>;
    nvidia,tristate = <1>;
   };

   pex_l1_clkreq_n_pdd6 {
    nvidia,pins = "pex_l1_clkreq_n_pdd6";
    nvidia,function = "safe";
    nvidia,enable-input = <0>;
    nvidia,pull = <1>;
    nvidia,tristate = <1>;
   };

   pex_l1_rst_n_pdd5 {
    nvidia,pins = "pex_l1_rst_n_pdd5";
    nvidia,function = "safe";
    nvidia,enable-input = <0>;
    nvidia,pull = <1>;
    nvidia,tristate = <1>;
   };

   pex_wake_n_pdd3 {
    nvidia,pins = "pex_wake_n_pdd3";
    nvidia,function = "safe";
    nvidia,enable-input = <0>;
    nvidia,pull = <1>;
    nvidia,tristate = <1>;
   };

   usb_vbus_en2_pff1 {
    nvidia,pins = "usb_vbus_en2_pff1";
    nvidia,function = "safe";
    nvidia,enable-input = <0>;
    nvidia,pull = <1>;
    nvidia,tristate = <1>;
   };

   pff2 {
    nvidia,pins = "pff2";
    nvidia,function = "safe";
    nvidia,enable-input = <0>;
    nvidia,pull = <1>;
    nvidia,tristate = <1>;
   };

   kb_col1_pq1 {
    nvidia,pins = "kb_col1_pq1";
    nvidia,function = "safe";
    nvidia,enable-input = <0>;
    nvidia,pull = <1>;
    nvidia,tristate = <1>;
   };

   kb_col4_pq4 {
    nvidia,pins = "kb_col4_pq4";
    nvidia,function = "safe";
    nvidia,enable-input = <0>;
    nvidia,pull = <1>;
    nvidia,tristate = <1>;
   };

   kb_row16_pt0 {
    nvidia,pins = "kb_row16_pt0";
    nvidia,function = "safe";
    nvidia,enable-input = <0>;
    nvidia,pull = <1>;
    nvidia,tristate = <1>;
   };

   kb_row17_pt1 {
    nvidia,pins = "kb_row17_pt1";
    nvidia,function = "safe";
    nvidia,enable-input = <0>;
    nvidia,pull = <1>;
    nvidia,tristate = <1>;
   };

   kb_row9_ps1 {
    nvidia,pins = "kb_row9_ps1";
    nvidia,function = "safe";
    nvidia,enable-input = <0>;
    nvidia,pull = <1>;
    nvidia,tristate = <1>;
   };

   clk3_out_pee0 {
    nvidia,pins = "clk3_out_pee0";
    nvidia,function = "safe";
    nvidia,enable-input = <0>;
    nvidia,pull = <1>;
    nvidia,tristate = <1>;
   };

   owr {
    nvidia,pins = "owr";
    nvidia,function = "safe";
    nvidia,enable-input = <0>;
    nvidia,pull = <1>;
    nvidia,tristate = <1>;
   };

   usb_vbus_en0_pn4 {
    nvidia,pins = "usb_vbus_en0_pn4";
    nvidia,function = "safe";
    nvidia,enable-input = <0>;
    nvidia,pull = <1>;
    nvidia,tristate = <1>;
   };

   usb_vbus_en1_pn5 {
    nvidia,pins = "usb_vbus_en1_pn5";
    nvidia,function = "safe";
    nvidia,enable-input = <0>;
    nvidia,pull = <1>;
    nvidia,tristate = <1>;
   };
  };
 };
};
# 7 "arch/arm/boot/dts/tegra124-loki-common.dtsi" 2
# 1 "/media/madman/Extended_Linux/21.8_l4t_build/kernel/arch/arm/boot/dts/tegra124-platforms/tegra124-loki-camera-a00.dtsi" 1
# 1 "/media/madman/Extended_Linux/21.8_l4t_build/kernel/arch/arm/boot/dts/include/dt-bindings/media/camera.h" 1
# 2 "/media/madman/Extended_Linux/21.8_l4t_build/kernel/arch/arm/boot/dts/tegra124-platforms/tegra124-loki-camera-a00.dtsi" 2

/ {
 camera-pcl {
  compatible = "nvidia,tegra124-camera", "simple-bus";
  configuration = <0xAA55AA55>;

  modules {
   module1: module1@modules {
    compatible = "sensor,front";
    badge_info = "loki_front_camera_device";

    sensor {
     profile = <&ov7695_1>;
     platformdata = "loki_ov7695_pdata";
    };
   };
  };

  profiles {
   ov7695_1: ov7695@2_0021 {
    index = <7>;
    chipname = "pcl_OV7695";
    type = "sensor";
    guid = "s_OV7695";
    position = <1>;
    bustype = "i2c";
    busnum = <2>;
    addr = <0x21>;
    datalen = <2>;
    pinmuxgrp = <0xFFFF>;
    gpios = <3>;
    regulators = "vana", "vif2";
    clocks = "mclk2";
    drivername = "ov7695";
    detect = <0x0002 0x300A 0xFFFF 0x7695>;
    devid = <0x7695>;
    poweron = <
     (0xf0000000 | 50) 10000
     (0xf0000000 | 31) 222
     (0xf0000000 | 20) (0x80000000 + 0)
     (0xf0000000 | 20) (0x80000000 + 1)
     (0xf0000000 | 2) 40
     (0xf0000000 | 30) 222
     (0xf0000000 | 2) 10
     (0xf0000000 | 9) 0
     >;
    poweroff = <
     (0xf0000000 | 50) 0
     (0xf0000000 | 31) 222
     (0xf0000000 | 1) 10
     (0xf0000000 | 20) 1
     (0xf0000000 | 20) 0
     (0xf0000000 | 9) 0
     >;
   };
  };
 };
};
# 8 "arch/arm/boot/dts/tegra124-loki-common.dtsi" 2


/ {
 model = "NVIDIA Tegra124 Loki";
 compatible = "nvidia,loki", "nvidia,tegra124";
 #address-cells = <2>;
 #size-cells = <2>;

 chosen {
  bootargs = "tegraid=40.0.0.00.00 vmalloc=256M video=tegrafb console=ttyS0,115200n8 earlyprintk";
  linux,initrd-start = <0x85000000>;
  linux,initrd-end = <0x851bc400>;
 };

 serial@70006000 {
  compatible = "nvidia,tegra114-hsuart";
  status = "okay";
 };

 serial@70006040 {
  compatible = "nvidia,tegra114-hsuart";
  status = "okay";
 };

 serial@70006200 {
  compatible = "nvidia,tegra114-hsuart";
  status = "okay";
 };

 memory@0x80000000 {
  device_type = "memory";
  reg = <0x0 0x80000000 0x0 0x80000000>;
 };

 i2c@7000c000 {
  bq2419x: bq2419x@6b {
   compatible = "ti,bq2419x";
   reg = <0x6b>;
   interrupt-parent = <&gpio>;
   interrupts = <72 0x0>;
   ti,charging-term-current-mA = <100>;

   vbus {
    regulator-name = "vbus_regulator";
    ti,otg-iusb-gpio = <&gpio ((8 * 8) + 4) 0>;
    consumers {
     c1 {
      regulator-consumer-supply = "usb_vbus";
      regulator-consumer-device = "tegra-ehci.0";
     };

     c2 {
      regulator-consumer-supply = "usb_vbus";
      regulator-consumer-device = "tegra-otg";
     };
    };
   };

   charger {
    regulator-name = "batt_regulator";
    regulator-max-microamp = <3000000>;
    ti,watchdog-timeout = <40>;
    ti,rtc-alarm-time = <3600>;
    ti,auto-recharge-time = <1800>;
    ti,temp-polling-time-sec = <5>;
    ti,disbale-suspend-during-charging;
    ti,pre-charge-current-limit-milliamp = <768>;
    ti,charge-term-current-limit-milliamp = <384>;
    ti,ir-comp-resister-ohm = <70>;
    ti,ir-comp-voltage-millivolt = <112>;
    ti,thermal-regulation-threshold-degc = <100>;
    consumers {
     c1 {
      regulator-consumer-supply = "usb_bat_chg";
      regulator-consumer-device = "tegra-udc.0";
     };

     c2 {
      regulator-consumer-supply = "usb_bat_chg";
      regulator-consumer-device = "tegra-otg";
     };

    };
   };
  };

  mpu6050@68 {
   compatible = "invensense,mpu6050";
   reg = <0x68>;
   interrupt-parent = <&gpio>;
   interrupts = <138 0x01>;
   invensense,int_config = <0x10>;
   invensense,level_shifter = <0>;
   invensense,orientation = [ff 00 00 00 01 00 00 00 ff];
   invensense,sec_slave_type = <0>;
   invensense,key = [4e cc 7e eb f6 1e 35 22
       00 34 0d 65 32 e9 94 89];
  };

  ak8975@0c {
   compatible = "ak,ak8975";
   reg = <0x0c>;
   orientation = [01 00 00 00 ff 00 00 00 ff];
   config = "mpu";
  };

  bq27441@55 {
   compatible = "ti,bq27441";
   reg = <0x55>;
   ti,design-capacity = <7800>;
   ti,design-energy = <28314>;
   ti,taper-rate = <167>;
   ti,terminate-voltage = <3150>;
   ti,v-at-chg-term = <4200>;
   ti,tz-name = "battery-temp";
  };

  jsa1127@39 {
   compatible = "solteam-opto,jsa1127";
   reg = <0x39>;
   solteam-opto,rint = <100>;
   solteam-opto,integration-time = <2000>;
   solteam-opto,use-internal-integration-timing = <1>;
   solteam-opto,tint-coeff = <22>;
   solteam-opto,noisy = <1>;
  };

  lc709203f@0b {
   compatible = "onsemi,lc709203f";
   reg = <0x0b>;
   onsemi,tz-name = "battery-temp";
  };
 };

 i2c@7000d000 {
  nvidia,bit-banging-xfer-after-shutdown;
 };

 spi@7000d400 {
  status = "okay";
  spi-max-frequency = <25000000>;
 };

 spi@7000da00 {
  status = "okay";
  spi-max-frequency = <25000000>;
 };

 gps {
  compatible = "mtk,mt3332";
  force-on-gpios = <&gpio ((7 * 8) + 5) 0>;
 };

 pmc {
  status = "okay";
  nvidia,invert-interrupt;
  nvidia,suspend-mode = <3>;
  nvidia,cpu-pwr-good-time = <500>;
  nvidia,cpu-pwr-off-time = <300>;
  nvidia,core-pwr-good-time = <3845 3845>;
  nvidia,core-pwr-off-time = <2000>;
  nvidia,core-power-req-active-high;
  nvidia,sys-clock-req-active-high;
 };

 xusb@70090000 {


  nvidia,gpio_ss1_sata = <0>;
  nvidia,portmap = <0x703>;
  nvidia,ss_portmap = <0x20>;
  nvidia,lane_owner = <6>;
  nvidia,ulpicap = <0>;
  status = "okay";
 };
};
# 2 "arch/arm/boot/dts/tegra124-loki-e2530-a01.dts" 2
# 1 "arch/arm/boot/dts/tegra124-platforms/tegra124-loki-powermon-e2530-a01.dtsi" 1
/ {
 i2c@7000c400 {
  ina3221x@40 {
   compatible = "ti,ina3221x";
   reg = <0x40>;
   ti,trigger-config = <0x7003>;
   ti,continuous-config = <0x7607>;
   #address-cells = <1>;
   #size-cells = <0>;

   channel@0 {
    reg = <0x0>;
    ti,rail-name = "VDD_BATT";
    ti,shunt-resistor-mohm = <10>;
    ti,current-critical-limit-ma = <6800>;
   };

   channel@1 {
    reg = <0x1>;
    ti,rail-name = "VDD_VBUS";
    ti,shunt-resistor-mohm = <10>;
   };

   channel@2 {
    reg = <0x2>;
    ti,rail-name = "VDD_MODEM";
    ti,shunt-resistor-mohm = <10>;
   };
  };
 };
};
# 3 "arch/arm/boot/dts/tegra124-loki-e2530-a01.dts" 2
# 1 "arch/arm/boot/dts/tegra124-platforms/tegra124-loki-pmic-e2530-0000-a01.dtsi" 1
# 1 "/media/madman/Extended_Linux/21.8_l4t_build/kernel/arch/arm/boot/dts/tegra124-platforms/tegra124-loki-pmic-e2545-0000-common.dtsi" 1

# 1 "/media/madman/Extended_Linux/21.8_l4t_build/kernel/arch/arm/boot/dts/include/dt-bindings/regulator/regulator.h" 1
# 3 "/media/madman/Extended_Linux/21.8_l4t_build/kernel/arch/arm/boot/dts/tegra124-platforms/tegra124-loki-pmic-e2545-0000-common.dtsi" 2
# 1 "/media/madman/Extended_Linux/21.8_l4t_build/kernel/arch/arm/boot/dts/include/dt-bindings/mfd/palmas.h" 1
# 4 "/media/madman/Extended_Linux/21.8_l4t_build/kernel/arch/arm/boot/dts/tegra124-platforms/tegra124-loki-pmic-e2545-0000-common.dtsi" 2

/ {
 i2c@7000d000 {
  palmas: tps65913 {
   compatible = "ti,palmas";
   reg = <0x58>;
   interrupts = <0 86 0>;

   #interrupt-cells = <2>;
   interrupt-controller;

   palmas_gpio: gpio {
    compatible = "ti,palmas-gpio";
    gpio-controller;
    #gpio-cells = <2>;
   };

   rtc {
    compatible = "ti,palmas-rtc";
    interrupt-parent = <&palmas>;
    interrupts = <8 0>;
   };

   pinmux {
    compatible = "ti,tps65913-pinctrl";
    pinctrl-names = "default";
    pinctrl-0 = <&palmas_default>;
    ti,palmas-enable-dvfs1;

    palmas_default: pinmux {
     powergood {
      pins = "powergood";
      function = "powergood";
     };

     vac {
      pins = "vac";
      function = "vac";
     };

     pin_gpio0 {
      pins = "gpio0";
      function = "id";
      bias-pull-up;
     };

     pin_gpio6 {
      pins = "gpio1", "gpio2", "gpio3", "gpio4", "gpio5", "gpio6", "gpio7";
      function = "gpio";
     };
    };
   };

   extcon {
    compatible = "ti,palmas-usb";
    extcon-name = "palmas-extcon";
    ti,wakeup;
    ti,enable-vbus-detection;
   };

   power_pm {
    compatible = "ti,palmas-pm";
    system-pmic-power-off;
    system-pmic-power-reset;
   };

   gpadc {
    compatible = "ti,palmas-gpadc";
    interrupt-parent = <&palmas>;
    interrupts = <18 0
           16 0
           17 0>;
    ti,channel3-current-microamp = <400>;
    ti,enable-channel3-dual-current;
    ti,enable-extended-delay;
   };

   clock {
    compatible = "ti,palmas-clk";

    clk32k_kg {
     ti,clock-boot-enable;
    };

    clk32k_kg_audio {
     ti,clock-boot-enable;
    };
   };

   pmic {
    compatible = "ti,tps65913-pmic", "ti,palmas-pmic";
    ldo1-in-supply = <&palmas_smps8>;
    ldo2-in-supply = <&palmas_smps6>;
    ldo3-in-supply = <&palmas_smps8>;
    ldo4-in-supply = <&palmas_smps6>;
    ldo5-in-supply = <&palmas_smps8>;
    ldo6-in-supply = <&palmas_smps6>;
    ldo9-in-supply = <&palmas_smps6>;

    regulators {
     smps123 {
      regulator-name = "vdd-gpu";
      regulator-min-microvolt = <650000>;
      regulator-max-microvolt = <1400000>;
      regulator-init-microvolt = <1000000>;

      regulator-boot-on;
      regulator-init-mode = <0x2>;

      consumers {
       c0 {
        regulator-consumer-supply = "vdd_gpu";
       };
      };
     };

     palmas_smps45: smps45 {
      regulator-name = "vdd-core";
      regulator-min-microvolt = <700000>;
      regulator-max-microvolt = <1250000>;
      regulator-init-mode = <0x2>;
      ti,roof-floor = <3>;
      regulator-ramp-delay = <2500>;

      consumers {
       c0 {
        regulator-consumer-supply = "vdd_core";
       };
      };
     };

     palmas_smps6: smps6 {
      regulator-name = "vdd-3v3";
      regulator-min-microvolt = <3300000>;
      regulator-max-microvolt = <3300000>;
      regulator-always-on;
      regulator-boot-on;
      regulator-init-mode = <0x2>;

      consumers {
       c0 {
        regulator-consumer-supply = "vdd_3v3_sys";
       };
      };
     };

     palmas_smps8: smps8 {
      regulator-name = "vdd-1v8";
      regulator-min-microvolt = <1800000>;
      regulator-max-microvolt = <1800000>;
      regulator-always-on;
      regulator-boot-on;
      regulator-init-mode = <0x2>;

      consumers {
       c0 {
        regulator-consumer-supply = "dbvdd";
        regulator-consumer-device = "tegra-snd-rt5639.0";
       };
       c1 {
        regulator-consumer-supply = "dbvdd";
        regulator-consumer-device = "tegra-snd-rt5645.0";
       };
       c2 {
        regulator-consumer-supply = "avdd";
        regulator-consumer-device = "tegra-snd-rt5639.0";
       };
       c3 {
        regulator-consumer-supply = "avdd";
        regulator-consumer-device = "tegra-snd-rt5645.0";
       };
       c4 {
        regulator-consumer-supply = "dmicvdd";
        regulator-consumer-device = "tegra-snd-rt5639.0";
       };
       c5 {
        regulator-consumer-supply = "dmicvdd";
        regulator-consumer-device = "tegra-snd-rt5645.0";
       };
       c6 {
        regulator-consumer-supply = "avdd_osc";
       };
       c7 {
        regulator-consumer-supply = "vddio_sys";
       };
       c8 {
        regulator-consumer-supply = "vddio_sys_2";
       };
       c9 {
        regulator-consumer-supply = "vddio_gmi";
       };
       c10 {
        regulator-consumer-supply = "pwrdet_nand";
       };
       c11 {
        regulator-consumer-supply = "vddio_sdmmc";
        regulator-consumer-device = "sdhci-tegra.0";
       };
       c12 {
        regulator-consumer-supply = "pwrdet_sdmmc1";
       };
       c13 {
        regulator-consumer-supply = "vddio_sdmmc";
        regulator-consumer-device = "sdhci-tegra.3";
       };
       c14 {
        regulator-consumer-supply = "pwrdet_sdmmc4";
       };
       c15 {
        regulator-consumer-supply = "avdd_pll_utmip";
        regulator-consumer-device = "tegra-udc.0";
       };
       c16 {
        regulator-consumer-supply = "avdd_pll_utmip";
        regulator-consumer-device = "tegra-ehci.0";
       };
       c17 {
        regulator-consumer-supply = "avdd_pll_utmip";
        regulator-consumer-device = "tegra-ehci.1";
       };
       c18 {
        regulator-consumer-supply = "avdd_pll_utmip";
        regulator-consumer-device = "tegra-ehci.2";
       };
       c19 {
        regulator-consumer-supply = "avdd_pll_utmip";
        regulator-consumer-device = "tegra-xhci";
       };
       c20 {
        regulator-consumer-supply = "vddio_audio";
       };
       c21 {
        regulator-consumer-supply = "pwrdet_audio";
       };
       c22 {
        regulator-consumer-supply = "vddio_uart";
       };
       c23 {
        regulator-consumer-supply = "pwrdet_uart";
       };
       c24 {
        regulator-consumer-supply = "vddio_bb";
       };
       c25 {
        regulator-consumer-supply = "pwrdet_bb";
       };
       c26 {
        regulator-consumer-supply = "vdd_dtv";
       };
       c27 {
        regulator-consumer-supply = "vdd_1v8_eeprom";
       };
       c28 {
        regulator-consumer-supply = "vddio_cam";
        regulator-consumer-device = "tegra_camera";
       };
       c29 {
        regulator-consumer-supply = "vddio_cam";
        regulator-consumer-device = "vi";
       };
       c30 {
        regulator-consumer-supply = "pwrdet_cam";
       };
       c31 {
        regulator-consumer-supply = "vlogic";
        regulator-consumer-device = "0-0068";
       };
       c32 {
        regulator-consumer-supply = "vid";
        regulator-consumer-device = "0-000c";
       };
       c33 {
        regulator-consumer-supply = "vddio";
        regulator-consumer-device = "0-0077";
       };
       c34 {
        regulator-consumer-supply = "vif";
        regulator-consumer-device = "2-0048";
       };
       c35 {
        regulator-consumer-supply = "vif2";
        regulator-consumer-device = "2-0021";
       };
      };
     };

     palmas_smps9: smps9 {
      regulator-name = "vddo-sdslot";
      regulator-min-microvolt = <2800000>;
      regulator-max-microvolt = <2800000>;
      regulator-init-mode = <0x1>;
      regulator-enable-ramp-delay = <250>;

      consumers {
       c0 {
        regulator-consumer-supply = "vddio_sd_slot";
        regulator-consumer-device = "sdhci-tegra.3";
       };
      };
     };

     palmas_smps10_out1: smps10_out1 {
      regulator-name = "vdd-cam-5v0";
      regulator-min-microvolt = <5000000>;
      regulator-max-microvolt = <5000000>;
      regulator-always-on;
      regulator-boot-on;

      consumers {
       c0 {
        regulator-consumer-supply = "vdd_5v0_cam";
       };
       c1 {
        regulator-consumer-supply = "spkvdd";
        regulator-consumer-device = "tegra-snd-rt5639.0";
       };
       c2 {
        regulator-consumer-supply = "spkvdd";
        regulator-consumer-device = "tegra-snd-rt5645.0";
       };
      };
     };

     palmas_ldo2: ldo2 {
      regulator-name = "avdd-lcd";
      regulator-min-microvolt = <2800000>;
      regulator-max-microvolt = <3100000>;

      consumers {
       c0 {
        regulator-consumer-supply = "avdd_lcd";
       };
       c1 {
        regulator-consumer-supply = "vana";
        regulator-consumer-device = "2-0048";
       };
       c2 {
        regulator-consumer-supply = "vdd";
        regulator-consumer-device = "0-0039";
       };
      };
     };

     palmas_ldo3: ldo3 {
      regulator-name = "avdd_dsi_csi";
      regulator-min-microvolt = <1200000>;
      regulator-max-microvolt = <1200000>;
      regulator-always-on;
      regulator-boot-on;

      consumers {
       c0 {
        regulator-consumer-supply = "avdd_dsi_csi";
        regulator-consumer-device = "tegradc.0";
       };
       c1 {
        regulator-consumer-supply = "avdd_dsi_csi";
        regulator-consumer-device = "tegradc.1";
       };
       c2 {
        regulator-consumer-supply = "avdd_dsi_csi";
        regulator-consumer-device = "vi.0";
       };
       c3 {
        regulator-consumer-supply = "avdd_dsi_csi";
        regulator-consumer-device = "vi.1";
       };
       c4 {
        regulator-consumer-supply = "pwrdet_mipi";
       };
       c5 {
        regulator-consumer-supply = "vddio_hsic";
        regulator-consumer-device = "tegra-ehci.1";
       };
       c6 {
        regulator-consumer-supply = "vddio_hsic";
        regulator-consumer-device = "tegra-ehci.2";
       };
       c7 {
        regulator-consumer-supply = "vddio_hsic";
        regulator-consumer-device = "tegra-xhci";
       };
      };
     };

     palmas_ldo4: ldo4 {
      regulator-name = "vpp-fuse";
      regulator-min-microvolt = <1800000>;
      regulator-max-microvolt = <1800000>;

      consumers {
       c0 {
        regulator-consumer-supply = "vpp_fuse";
       };
      };
     };

     palmas_ldo6: ldo6 {
      regulator-name = "vdd-sensor";
      regulator-min-microvolt = <2800000>;
      regulator-max-microvolt = <2800000>;

      consumers {
       c0 {
        regulator-consumer-supply = "vdd_snsr";
       };
       c1 {
        regulator-consumer-supply = "vdd";
        regulator-consumer-device = "0-000c";
       };
       c2 {
        regulator-consumer-supply = "vdd";
        regulator-consumer-device = "0-0077";
       };
       c3 {
        regulator-consumer-supply = "vdd";
        regulator-consumer-device = "0-004c";
       };
       c4 {
        regulator-consumer-supply = "vdd";
        regulator-consumer-device = "0-0068";
       };
       c5 {
        regulator-consumer-supply = "vana";
        regulator-consumer-device = "2-0021";
       };
      };
     };

     palmas_ldo8: ldo8 {
      regulator-name = "vdd-cpu";
      regulator-min-microvolt = <900000>;
      regulator-max-microvolt = <900000>;
      regulator-always-on;
      regulator-boot-on;

      consumers {
       c0 {
        regulator-consumer-supply = "vdd_rtc";
       };
      };
     };

     palmas_ldo9: ldo9 {
      regulator-name = "vddio-sdmmc3";
      regulator-min-microvolt = <1800000>;
      regulator-max-microvolt = <3300000>;

      consumers {
       c0 {
        regulator-consumer-supply = "vddio_sdmmc";
        regulator-consumer-device = "sdhci-tegra.2";
       };
       c1 {
        regulator-consumer-supply = "pwrdet_sdmmc3";
       };
      };
     };

     palmas_ldoln: ldoln {
      regulator-name = "vdd-ldoln";
      regulator-min-microvolt = <2800000>;
      regulator-max-microvolt = <3300000>;
     };

     palmas_ldousb: ldousb {
      regulator-name = "vddio-hv";
      regulator-min-microvolt = <2300000>;
      regulator-max-microvolt = <3300000>;

      consumers {
       c0 {
        regulator-consumer-supply = "vddio_hv";
        regulator-consumer-device = "tegradc.0";
       };
       c1 {
        regulator-consumer-supply = "vddio_hv";
        regulator-consumer-device = "tegradc.1";
       };
       c2 {
        regulator-consumer-supply = "pwrdet_hv";
       };
       c3 {
        regulator-consumer-supply = "vddio_pex_ctl";
        regulator-consumer-device = "tegra-pcie";
       };
       c4 {
        regulator-consumer-supply = "pwrdet_pex_ctl";
       };
       c5 {
        regulator-consumer-supply = "avdd_hdmi";
        regulator-consumer-device = "tegradc.0";
       };
       c6 {
        regulator-consumer-supply = "avdd_hdmi";
        regulator-consumer-device = "tegradc.1";
       };
       c7 {
        regulator-consumer-supply = "avdd_usb";
        regulator-consumer-device = "tegra-udc.0";
       };
       c8 {
        regulator-consumer-supply = "avdd_usb";
        regulator-consumer-device = "tegra-ehci.0";
       };
       c9 {
        regulator-consumer-supply = "avdd_usb";
        regulator-consumer-device = "tegra-ehci.1";
       };
       c10 {
        regulator-consumer-supply = "avdd_usb";
        regulator-consumer-device = "tegra-ehci.2";
       };
       c11 {
        regulator-consumer-supply = "hvdd_usb";
        regulator-consumer-device = "tegra-xhci";
       };
       c12 {
        regulator-consumer-supply = "hvdd_pex";
        regulator-consumer-device = "tegra-pcie";
       };
       c13 {
        regulator-consumer-supply = "hvdd_pex_pll_e";
        regulator-consumer-device = "tegra-pcie";
       };
       c14 {
        regulator-consumer-supply = "hvdd_sata";
        regulator-consumer-device = "tegra-sata.0";
       };
      };
     };

     palmas_regen1: regen1 {
      regulator-name = "vdd-regen1";
      regulator-max-microvolt = <3300000>;
     };

     palmas_regen2:regen2 {
      regulator-name = "vdd-regen2";
      regulator-max-microvolt = <5000000>;
      regulator-always-on;
      regulator-boot-on;
     };
    };
   };
  };
 };
};
# 2 "arch/arm/boot/dts/tegra124-platforms/tegra124-loki-pmic-e2530-0000-a01.dtsi" 2

/ {
 i2c@7000d000 {
  tps65913 {
   pmic {
    regulators {
     palmas_smps7: smps7 {
      regulator-name = "vddio-ddr";
      regulator-min-microvolt = <1500000>;
      regulator-max-microvolt = <1500000>;
      regulator-init-mode = <0x2>;
      regulator-always-on;
      regulator-boot-on;

      consumers {
       c0 {
        regulator-consumer-supply = "vddio_ddr";
       };
       c1 {
        regulator-consumer-supply = "vddio_ddr_mclk";
       };
      };
     };

     palmas_ldo1: ldo1 {
      regulator-name = "avdd-pll";
      regulator-min-microvolt = <1050000>;
      regulator-max-microvolt = <1050000>;
      regulator-always-on;
      regulator-boot-on;
      ti,roof-floor = <3>;

      consumers {
       c0 {
        regulator-consumer-supply = "avdd_pll_m";
       };
       c1 {
        regulator-consumer-supply = "avdd_pll_ap_c2_c3";
       };
       c2 {
        regulator-consumer-supply = "avdd_pll_cud2dpd";
       };
       c3 {
        regulator-consumer-supply = "avdd_pll_c4";
       };
       c4 {
        regulator-consumer-supply = "avdd_lvds0_io";
       };
       c6 {
        regulator-consumer-supply = "avdd_pll_erefe";
       };
       c7 {
        regulator-consumer-supply = "avdd_pll_x";
       };
       c8 {
        regulator-consumer-supply = "avdd_pll_cg";
       };
       c9 {
        regulator-consumer-supply = "avdd_pex_pll";
        regulator-consumer-device = "tegra-pcie";
       };
       c10 {
        regulator-consumer-supply = "avddio_pex";
        regulator-consumer-device = "tegra-pcie";
       };
       c11 {
        regulator-consumer-supply = "dvddio_pex";
        regulator-consumer-device = "tegra-pcie";
       };
       c12 {
        regulator-consumer-supply = "avddio_usb";
        regulator-consumer-device = "tegra-xhci";
       };
       c13 {
        regulator-consumer-supply = "vdd_sata";
        regulator-consumer-device = "tegra-sata.0";
       };
       c14 {
        regulator-consumer-supply = "avdd_sata";
        regulator-consumer-device = "tegra-sata.0";
       };
       c15 {
        regulator-consumer-supply = "avdd_sata_pll";
        regulator-consumer-device = "tegra-sata.0";
       };

       c5 {
        regulator-consumer-supply = "avdd_hdmi_pll";
        regulator-consumer-device = "tegradc.1";
       };
      };
     };

     palmas_ldo5: ldo5 {
      regulator-name = "vddio-ddr-hs";
      regulator-min-microvolt = <1100000>;
      regulator-max-microvolt = <1100000>;
      regulator-always-on;
      regulator-boot-on;
      ti,roof-floor = <3>;

      consumers {
       c0 {
        regulator-consumer-supply = "vddio_ddr_hs";
       };
      };
     };
    };
   };
  };
 };
};
# 4 "arch/arm/boot/dts/tegra124-loki-e2530-a01.dts" 2
# 1 "arch/arm/boot/dts/tegra124-platforms/tegra124-loki-fixed-e2530-0000-a00.dtsi" 1
# 1 "arch/arm/boot/dts/tegra124-platforms/tegra124-loki-fixed-e2545-0000-common.dtsi" 1


/ {
 regulators {
  compatible = "simple-bus";
  device_type = "fixed-regulators";
  #address-cells = <1>;
  #size-cells = <0>;

  en_battery: regulator@0 {
   compatible = "regulator-fixed";
   reg = <0>;
   regulator-name = "vdd_ac_bat";
   regulator-min-microvolt = <3300000>;
   regulator-max-microvolt = <3300000>;
   regulator-always-on;

   consumers {
    c0 {
     regulator-consumer-supply = "vdd_sys_bl";
    };
    c1 {
     regulator-consumer-supply = "usb_vbus";
     regulator-consumer-device = "tegra-ehci.1";
    };
    c2 {
     regulator-consumer-supply = "usb_vbus";
     regulator-consumer-device = "tegra-ehci.2";
    };
    c3 {
     regulator-consumer-supply = "usb_vbus1";
     regulator-consumer-device = "tegra-xhci";
    };
    c4 {
     regulator-consumer-supply = "usb_vbus2";
     regulator-consumer-device = "tegra-xhci";
    };
    c5 {
     regulator-consumer-supply = "vddio_pex_sata";
     regulator-consumer-device = "tegra-sata.0";
    };
   };
  };

  en_modem_3v3: regulator@1 {
   compatible = "regulator-fixed-sync";
   reg = <1>;
   regulator-name = "vdd-wwan";
   regulator-min-microvolt = <3700000>;
   regulator-max-microvolt = <3700000>;
   gpio = <&gpio ((18 * 8) + 2) 0>;
   enable-active-high;
   vin-supply = <&palmas_smps10_out1>;

   consumers {
    c0 {
     regulator-consumer-supply = "vdd_wwan_mdm";
    };
   };
  };

  en_vdd_hdmi_5v0: regulator@2 {
   compatible = "regulator-fixed-sync";
   reg = <2>;
   regulator-name = "vdd-hdmi-5v0";
   regulator-min-microvolt = <5000000>;
   regulator-max-microvolt = <5000000>;
   gpio = <&gpio ((18 * 8) + 5) 0>;
   enable-active-high;
   vin-supply = <&palmas_smps6>;
   startup-delay-us = <5000>;

   consumers {
    c0 {
     regulator-consumer-supply = "vdd_hdmi_5v0";
     regulator-consumer-device = "tegradc.0";
    };
    c1 {
     regulator-consumer-supply = "vdd_hdmi_5v0";
     regulator-consumer-device = "tegradc.1";
    };
   };
  };

  en_vdd_sd_slot: regulator@3 {
   compatible = "regulator-fixed-sync";
   reg = <3>;
   regulator-name = "vdd-sd2-slot";
   regulator-min-microvolt = <3300000>;
   regulator-max-microvolt = <3300000>;
   regulator-always-on;
   gpio = <&gpio ((17 * 8) + 0) 0>;
   enable-active-high;
   vin-supply = <&palmas_smps6>;

   consumers {
    c0 {
     regulator-consumer-supply = "vddio_sd_slot";
     regulator-consumer-device = "sdhci-tegra.2";
    };
   };
  };

  en_1v8_ts: regulator@4 {
   compatible = "regulator-fixed-sync";
   reg = <4>;
   regulator-name = "vdd-ts-1v8";
   regulator-min-microvolt = <1800000>;
   regulator-max-microvolt = <1800000>;
   gpio = <&gpio ((10 * 8) + 1) 0>;
   enable-active-high;
   vin-supply = <&palmas_smps8>;

   consumers {
    c0 {
     regulator-consumer-supply = "dvdd";
     regulator-consumer-device = "spi0.0";
    };
   };
  };

  en_3v3_ts: regulator@5 {
   compatible = "regulator-fixed-sync";
   reg = <5>;
   regulator-name = "vdd-ts-3v3";
   regulator-min-microvolt = <3300000>;
   regulator-max-microvolt = <3300000>;
   gpio = <&gpio ((7 * 8) + 0) 0>;
   enable-active-high;
   vin-supply = <&palmas_smps6>;

   consumers {
    c0 {
     regulator-consumer-supply = "avdd";
     regulator-consumer-device = "spi0.0";
    };
   };
  };

  en_1v8_display: regulator@6 {
   compatible = "regulator-fixed";
   reg = <6>;
   regulator-name = "display-1v8";
   regulator-min-microvolt = <1800000>;
   regulator-max-microvolt = <1800000>;

   consumers {
    c0 {
     regulator-consumer-supply = "vdd_lcd_1v8_s";
    };
   };
  };

  en_vdd_cpu_fixed: regulator@7 {
   compatible = "regulator-fixed";
   reg = <7>;
   regulator-name = "vdd-cpu-fixed";
   regulator-min-microvolt = <1000000>;
   regulator-max-microvolt = <1000000>;
   consumers {
    c0 {
     regulator-consumer-supply = "vdd_cpu_fixed";
    };
   };
  };

  en_lcd_bl: regulator@8 {
   compatible = "regulator-fixed-sync";
   reg = <8>;
   regulator-name = "lcd-bl";
   regulator-min-microvolt = <5000000>;
   regulator-max-microvolt = <5000000>;
   regulator-boot-on;
   gpio = <&gpio ((7 * 8) + 2) 0>;
   enable-active-high;
   startup-delay-us = <1000>;
   consumers {
    c0 {
     regulator-consumer-supply = "vdd_lcd_bl_en";
    };
   };
  };

  en_com_3v3: regulator@9 {
   compatible = "regulator-fixed-sync";
   reg = <9>;
   regulator-name = "vdd-com-3v3";
   regulator-min-microvolt = <3300000>;
   regulator-max-microvolt = <3300000>;
   gpio = <&gpio ((23 * 8) + 1) 0>;
   enable-active-high;
   vin-supply = <&palmas_smps6>;
   startup-delay-us = <1000>;
   consumers {
    c0 {
     regulator-consumer-supply = "avdd";
     regulator-consumer-device = "bcm4329_wlan.1";
    };
    c1 {
     regulator-consumer-supply = "avdd";
     regulator-consumer-device = "bluedroid_pm.0";
    };
   };
  };

  en_com_1v8: regulator@10 {
   compatible = "regulator-fixed-sync";
   reg = <10>;
   regulator-name = "vdd-com-1v8";
   regulator-min-microvolt = <1800000>;
   regulator-max-microvolt = <1800000>;
   gpio = <&gpio ((23 * 8) + 7) 0>;
   enable-active-high;
   vin-supply = <&palmas_smps8>;
   startup-delay-us = <1000>;
   consumers {
    c0 {
     regulator-consumer-supply = "dvdd";
     regulator-consumer-device = "bcm4329_wlan.1";
    };
    c1 {
     regulator-consumer-supply = "dvdd";
     regulator-consumer-device = "bluedroid_pm.0";
    };
   };
  };

  en_dvdd_lcd: regulator@11 {
   compatible = "regulator-fixed-sync";
   reg = <11>;
   regulator-name = "dvdd-lcd";
   regulator-min-microvolt = <1800000>;
   regulator-max-microvolt = <1800000>;
   regulator-boot-on;
   gpio = <&gpio ((20 * 8) + 4) 0>;
   enable-active-high;
   vin-supply = <&palmas_smps8>;
   consumers {
    c0 {
     regulator-consumer-supply = "dvdd_lcd";
    };
   };
  };
 };
};
# 2 "arch/arm/boot/dts/tegra124-platforms/tegra124-loki-fixed-e2530-0000-a00.dtsi" 2

/ {
 regulators {
  regulator@2 {
   gpio = <&gpio ((31 * 8) + 0) 0>;
  };
 };
};
# 5 "arch/arm/boot/dts/tegra124-loki-e2530-a01.dts" 2

/ {
 nvidia,dtsfilename = "arch/arm/boot/dts/tegra124-loki-e2530-a01.dts";

 i2c@7000d000 {
  tps65913 {
   gpadc {
    ti,auto-conversion-period-ms = <1000>;
    auto_conv1 {
     ti,adc-channel-number = <4>;
     ti,adc-low-threshold = <748>;
     ti,enable-shutdown;
    };

    iio_map {
     ch1 {
      ti,adc-channel-number = <1>;
      ti,adc-consumer-device = "generic-adc-thermal.0";
      ti,adc-consumer-channel ="thermistor";
     };

     ch3 {
      ti,adc-channel-number = <3>;
      ti,adc-consumer-device = "generic-adc-thermal.1";
      ti,adc-consumer-channel ="tdiode";
     };

     ch4 {
      ti,adc-channel-number = <4>;
      ti,adc-consumer-device = "generic-adc-thermal.2";
      ti,adc-consumer-channel ="tbat";
     };
    };
   };
  };
 };
};
# 2 "arch/arm/boot/dts/tegra124-loki.dts" 2

/ {
 nvidia,dtsfilename = "arch/arm/boot/dts/tegra124-loki.dts";
};
